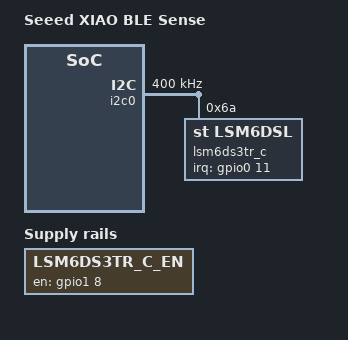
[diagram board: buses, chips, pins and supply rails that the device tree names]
/*
 * Copyright (c) 2022-2023 Marcin Niestroj
 *
 * SPDX-License-Identifier: Apache-2.0
 */

/dts-v1/;
#include "xiao_ble_common.dtsi"
#include <zephyr/dt-bindings/i2c/i2c.h>
#include <zephyr/dt-bindings/gpio/nordic-nrf-gpio.h>

/ {
	model = "Seeed XIAO BLE Sense";
	compatible = "seeed,xiao-ble", "seeed,xiao-ble-sense";

	lsm6ds3tr-c-en {
		compatible = "regulator-fixed-sync", "regulator-fixed";
		enable-gpios = <&gpio1 8 (NRF_GPIO_DRIVE_S0H1 | GPIO_ACTIVE_HIGH)>;
		regulator-name = "LSM6DS3TR_C_EN";
		regulator-boot-on;
		startup-delay-us = <900>;
	};
};

&i2c0 {
	compatible = "nordic,nrf-twim";
	/* Cannot be used together with spi0. */
	status = "okay";
	pinctrl-0 = <&i2c0_default>;
	pinctrl-1 = <&i2c0_sleep>;
	pinctrl-names = "default", "sleep";
	clock-frequency = <I2C_BITRATE_FAST>;

	lsm6ds3tr_c: lsm6ds3tr-c@6a {
		compatible = "st,lsm6dsl";
		reg = <0x6a>;
		irq-gpios = <&gpio0 11 GPIO_ACTIVE_HIGH>;
		status = "okay";
	};
};
